# TREMO register map
File version: 1.6.2
CPU: CM4 r0p1, little endian, MPU, FPU, 3 interrupt priority bits
Registers are 32-bit, read-write, reset 0x0 unless marked. A register's access mark holds for its fields unless they carry their own. Offsets are from the block's base; [hi:lo] are bit positions; {n}, {i} and the like mark numbered series.

## LCD
Base 0x40018000
0x00 CR0 — control register 0
0x04 CR1 — control register 1
{0x8+4i} DR{i} (i=0..7) — data register {i}
0x28 SR ro — status register
0x2C CR2 — control register 2

## LORAC
Base 0x40009000
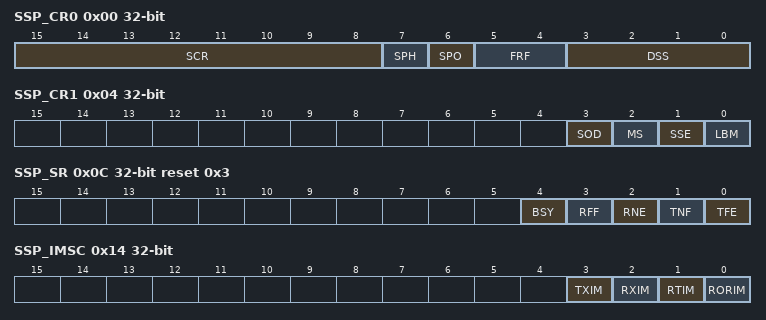
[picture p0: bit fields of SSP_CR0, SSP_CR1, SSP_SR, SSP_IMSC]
0x00 SSP_CR0 — ssp control register 0
  [15:8] SCR — Serial clock rate
  [7] SPH — SSP phase setting
  [6] SPO — SSP polarity setting
  [5:4] FRF — SSP frame formats setting
  [3:0] DSS — Data width setting
0x04 SSP_CR1 — ssp control register 1
  [3] SOD — SSP output disable in slave mode
  [2] MS — Master/slave mode selection
  [1] SSE — SSP enable
  [0] LBM — loopback mode
0x08 SSP_DR — ssp data register
  [15:0] DATA — SSP TX/RX data
0x0C SSP_SR ro reset 0x3 — ssp status register
  [4] BSY — SSP busy flag
  [3] RFF — RX FIFO full flag
  [2] RNE — RX FIFO not empty flag
  [1] TNF — TX FIFO not full flag
  [0] TFE — TX FIFO empty flag
0x10 SSP_CPSR — ssp clock prescale register
  [7:0] CPSDVSR — Clock prescaler divider
0x14 SSP_IMSC — ssp interrupt mask set or clear register
  [3] TXIM — TX interrupt mask bit
  [2] RXIM — RX interrupt mask bit
  [1] RTIM — RX timeout interrupt mask bit
  [0] RORIM — RX overrun interrupt mask bit
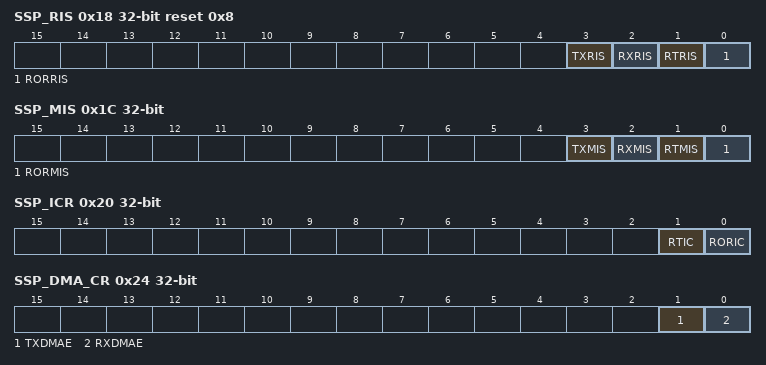
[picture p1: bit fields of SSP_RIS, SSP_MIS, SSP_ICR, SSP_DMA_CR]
0x18 SSP_RIS ro reset 0x8 — ssp raw interrupt status register
  [3] TXRIS — TX raw interrupt status
  [2] RXRIS — RX raw interrupt status
  [1] RTRIS — RX timeout raw interrupt status
  [0] RORRIS — RX overrun raw interrupt status
0x1C SSP_MIS ro — ssp masked interrupt status register
  [3] TXMIS — TX masked interrupt status
  [2] RXMIS — RX masked interrupt status
  [1] RTMIS — RX timeout masked interrupt status
  [0] RORMIS — RX overrun masked interrupt status
0x20 SSP_ICR wo — ssp interrupt clear register
  [1] RTIC — RX timeout interrupt clear
  [0] RORIC — RX overrun interrupt clear
0x24 SSP_DMA_CR — ssp DMA control register
  [1] TXDMAE — DMA TX enable
  [0] RXDMAE — DMA RX enable
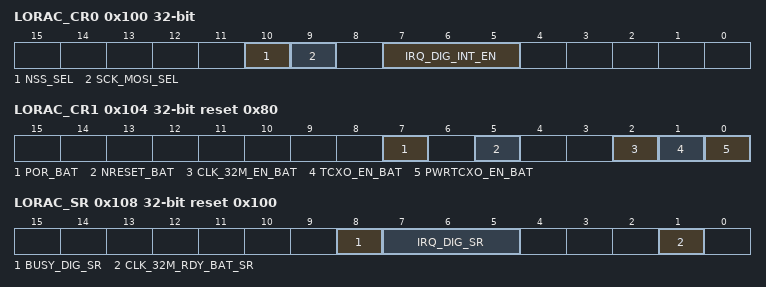
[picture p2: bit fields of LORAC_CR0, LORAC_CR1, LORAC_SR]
0x100 LORAC_CR0 — control register 0
  [10] NSS_SEL — NSS source selection for RF TRX
  [9] SCK_MOSI_SEL — SCK/MOSI/MISO source selection for RF TRX
  [7:5] IRQ_DIG_INT_EN — IRQ_DIG_INT high level interrupt enable
0x104 LORAC_CR1 reset 0x80 — control register 1
  [7] POR_BAT — POR_BAT control
  [5] NRESET_BAT — NRESET_BAT control
  [2] CLK_32M_EN_BAT — CLK_32M_EN_BAT control
  [1] TCXO_EN_BAT — TCXO_EN_BAT control
  [0] PWRTCXO_EN_BAT — PWRTCXO_EN_BAT control
0x108 LORAC_SR ro reset 0x100 — status register
  [8] BUSY_DIG_SR — BUSY_DIG status flag
  [7:5] IRQ_DIG_SR — IRQ_DIG flag
  [1] CLK_32M_RDY_BAT_SR — CLK_32M_RDY_BAT status flag
0x10C LORAC_NSS_CR reset 0x1 — nss control register
  [0] REG_NSS — NSS control bit
0x110 LORAC_SCK_CR — sck control register
  [0] REG_SCK — SCK control bit
0x114 LORAC_MOSI_CR — mosi control register
  [0] REG_MOSI — MOSI control bit
0x118 LORAC_MISO_SR ro — miso control register
  [0] REG_MISO

## AFEC
Base 0x40008000
0x200 CR — control register
0x204 INT_SR — interrupt status register
  [31:0] CR
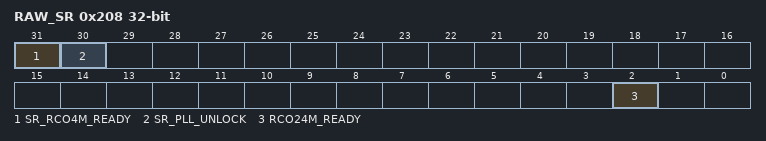
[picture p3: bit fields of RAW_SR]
0x208 RAW_SR ro — raw status register
  [31] SR_RCO4M_READY, [30] SR_PLL_UNLOCK, [2] RCO24M_READY

## IWDG — Independent watchdog
Base 0x4001D000
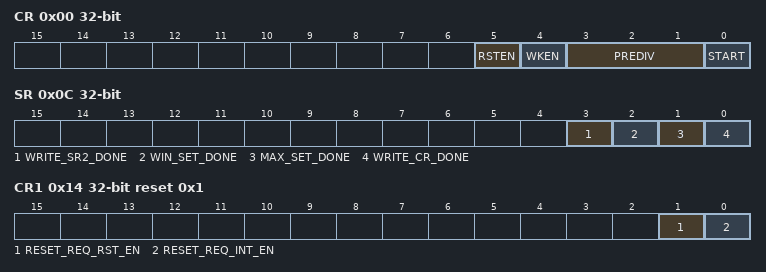
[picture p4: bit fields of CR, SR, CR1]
0x00 CR — control register
  [5] RSTEN, [4] WKEN, [3:1] PREDIV, [0] START
0x04 MAX — max value register
0x08 WIN — window value register
0x0C SR ro — status register
  [3] WRITE_SR2_DONE rw, [2] WIN_SET_DONE, [1] MAX_SET_DONE, [0] WRITE_CR_DONE
0x10 SR1 ro — status register 1
  [12] RESET_REQ_SYNC rw
0x14 CR1 reset 0x1 — control register 1
  [1] RESET_REQ_RST_EN, [0] RESET_REQ_INT_EN
0x18 SR2 — status register 2
  [0] RESET_REQ_SR

## WDG — Watchdog timer
Base 0x4001E000
0x00 LOAD
  [31:0] DATA
0x04 VALUE ro
  [31:0] DATA rw
0x08 CONTROL
0x0C INTCLR wo — clear interrupt register
  [31:0] DATA rw
0x10 RIS ro — raw interrupt status register
0x14 MIS ro — interrupt status register
0xC00 LOCK
0xF00 ITCR — integration test control register
0xF04 ITOP wo — integration test output set register
  [31:0] ITOP rw
0xFD0 PERIPHID4 ro — peripheral id register 4
  [0] PERIPHID
{0xFC0+4i} PERIPHID{i} ro (i=5..7) — peripheral id register {i}
  [31:0] PERIPHID
{0xFE0+4i} PERIPHID{i} ro (i=0..3) — peripheral id register {i}
  [31:0] PERIPHID
{0xFF0+4i} PCELLID{i} ro (i=0..3) — component id register {i}
  [31:0] PCELLID
